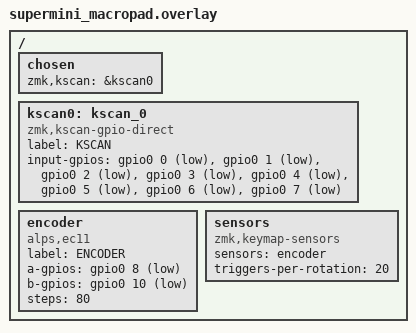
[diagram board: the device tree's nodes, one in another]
#include <dt-bindings/zmk/matrix_transform.h>

/ {
    chosen {
        zmk,kscan = &kscan0;
    };

    kscan0: kscan_0 {
        compatible = "zmk,kscan-gpio-direct";
        label = "KSCAN";
        input-gpios
            = <&gpio0 0 (GPIO_ACTIVE_LOW | GPIO_PULL_UP)>
            , <&gpio0 1 (GPIO_ACTIVE_LOW | GPIO_PULL_UP)>
            , <&gpio0 2 (GPIO_ACTIVE_LOW | GPIO_PULL_UP)>
            , <&gpio0 3 (GPIO_ACTIVE_LOW | GPIO_PULL_UP)>
            , <&gpio0 4 (GPIO_ACTIVE_LOW | GPIO_PULL_UP)>
            , <&gpio0 5 (GPIO_ACTIVE_LOW | GPIO_PULL_UP)>
            , <&gpio0 6 (GPIO_ACTIVE_LOW | GPIO_PULL_UP)>
            , <&gpio0 7 (GPIO_ACTIVE_LOW | GPIO_PULL_UP)>
            ;
    };

    encoder: encoder {
        compatible = "alps,ec11";
        label = "ENCODER";
        a-gpios = <&gpio0 8 (GPIO_ACTIVE_LOW | GPIO_PULL_UP)>;
        b-gpios = <&gpio0 10 (GPIO_ACTIVE_LOW | GPIO_PULL_UP)>;
        steps = <80>;
        status = "okay";
    };

    sensors: sensors {
        compatible = "zmk,keymap-sensors";
        sensors = <&encoder>;
        triggers-per-rotation = <20>;
    };
};

/* Note: ARGB/WS2812 support removed for initial build.
   ESP32-C3 requires specific SPI/RMT driver configuration
   which can be added once basic functionality is confirmed. */
